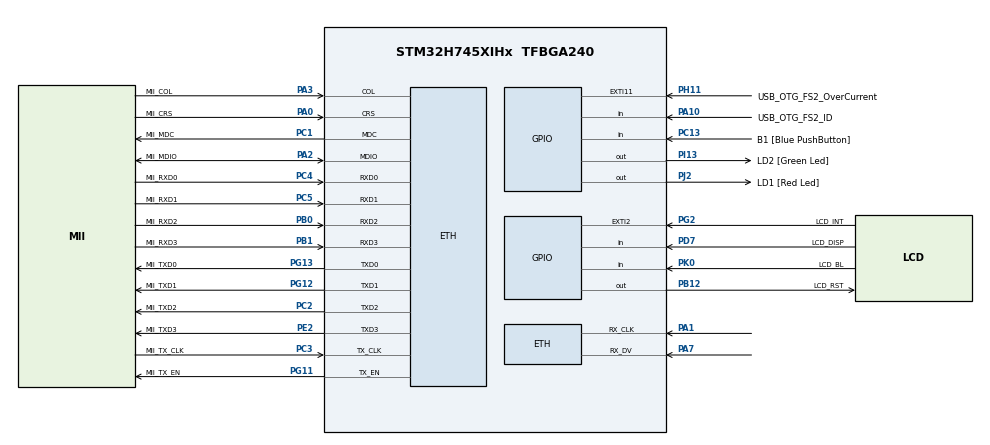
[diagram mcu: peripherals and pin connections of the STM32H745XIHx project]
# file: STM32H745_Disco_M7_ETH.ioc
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CORTEX_M7.AccessPermission_S-Cortex_Memory_Protection_Unit_Region1_Settings_S=MPU_REGION_FULL_ACCESS
CORTEX_M7.AccessPermission_S-Cortex_Memory_Protection_Unit_Region2_Settings_S=MPU_REGION_FULL_ACCESS
CORTEX_M7.BaseAddress_S-Cortex_Memory_Protection_Unit_Region1_Settings_S=0x30020000
CORTEX_M7.BaseAddress_S-Cortex_Memory_Protection_Unit_Region2_Settings_S=0x30040000
CORTEX_M7.CPU_DCache=Enabled
CORTEX_M7.CPU_ICache=Enabled
CORTEX_M7.DisableExec_S-Cortex_Memory_Protection_Unit_Region1_Settings_S=MPU_INSTRUCTION_ACCESS_DISABLE
CORTEX_M7.DisableExec_S-Cortex_Memory_Protection_Unit_Region2_Settings_S=MPU_INSTRUCTION_ACCESS_DISABLE
CORTEX_M7.Enable_S-Cortex_Memory_Protection_Unit_Region1_Settings_S=MPU_REGION_ENABLE
CORTEX_M7.Enable_S-Cortex_Memory_Protection_Unit_Region2_Settings_S=MPU_REGION_ENABLE
CORTEX_M7.IsBufferable_S-Cortex_Memory_Protection_Unit_Region2_Settings_S=MPU_ACCESS_BUFFERABLE
CORTEX_M7.IsShareable_S-Cortex_Memory_Protection_Unit_Region2_Settings_S=MPU_ACCESS_SHAREABLE
CORTEX_M7.Size_S-Cortex_Memory_Protection_Unit_Region1_Settings_S=MPU_REGION_SIZE_128KB
CORTEX_M7.Size_S-Cortex_Memory_Protection_Unit_Region2_Settings_S=MPU_REGION_SIZE_512B
CORTEX_M7.TypeExtField_S-Cortex_Memory_Protection_Unit_Region1_Settings_S=MPU_TEX_LEVEL1
CORTEX_M7.default_mode_Activation=1
CortexM4.IPs=FATFS_M4\:I,FREERTOS_M4\:I,IWDG2\:I,RCC,USB_DEVICE_M4\:I,USB_HOST_M4\:I,WWDG2\:I,DMA,BDMA,MDMA,NVIC2\:I,SAI4\:I,DEBUG,PDM2PCM_M4\:I,PWR,RESMGR_UTILITY,SYS_M4\:I,CORTEX_M4\:I,OPENAMP_M4\:I,VREFBUF
CortexM7.IPs=FATFS_M7\:I,FREERTOS_M7\:I,IWDG1\:I,RCC\:I,USB_DEVICE_M7\:I,USB_HOST_M7\:I,WWDG1\:I,DMA\:I,BDMA\:I,MDMA\:I,NVIC1\:I,CORTEX_M7\:I,DEBUG\:I,PDM2PCM_M7\:I,PWR\:I,RESMGR_UTILITY\:I,SYS\:I,OPENAMP_M7\:I,VREFBUF\:I,TIM6\:I,ETH\:I,LWIP\:I
ETH.MediaInterface=HAL_ETH_MII_MODE
ETH.RxBuffAddress=0x30000200
ETH.RxBuffLen=1536
ETH.TxDescAddress=0x30000100
FREERTOS_M7.Tasks01=defaultTask,24,512,StartDefaultTask,Default,NULL,Dynamic,NULL,NULL
FREERTOS_M7.configCHECK_FOR_STACK_OVERFLOW=1
FREERTOS_M7.configMINIMAL_STACK_SIZE=512
FREERTOS_M7.configTOTAL_HEAP_SIZE=30*1024
FREERTOS_M7.configUSE_NEWLIB_REENTRANT=1
LWIP.BSP.number=1
LWIP.DEFAULT_THREAD_STACKSIZE=2048
LWIP.IP_ADDRESS=192.168.001.010
LWIP.LWIP_DHCP=0
LWIP.LWIP_RAM_HEAP_POINTER=0x30020000
LWIP.MEM_SIZE=131048
LWIP.NETMASK_ADDRESS=255.255.255.000
LWIP.TCPIP_THREAD_STACKSIZE=2048
LWIP.TCP_MSS=1460
LWIP.TCP_SND_BUF=5840
LWIP.TCP_SND_QUEUELEN=16
LWIP.Version=v2.1.2_Cube
LWIP0.BSP.STBoard=false
LWIP0.BSP.api=BSP_COMPONENT_DRIVER
LWIP0.BSP.component=LAN8742
LWIP0.BSP.i2caddr=0
LWIP0.BSP.instance=LAN8742
LWIP0.BSP.name=Driver_PHY
LWIP0.BSP.semaphore=S_LAN8742
LWIP0.BSP.solution=LAN8742
Mcu.Family=STM32H7
Mcu.Name=STM32H745XIHx
Mcu.Package=TFBGA240
NVIC1.ETH_IRQn=true\:5\:0\:false\:false\:true\:true\:true\:true\:true
NVIC1.PriorityGroup=NVIC_PRIORITYGROUP_4
NVIC1.TIM6_DAC_IRQn=true\:15\:0\:false\:false\:true\:false\:false\:true\:true
NVIC1.TimeBase=TIM6_DAC_IRQn
NVIC1.TimeBaseIP=TIM6
NVIC2.PriorityGroup=NVIC_PRIORITYGROUP_4
PA0.GPIO_Label=MII_CRS
PA0.GPIO_Speed=GPIO_SPEED_FREQ_VERY_HIGH
PA0.Mode=MII
PA0.PinAttribute=CortexM7
PA0.Signal=ETH_CRS
PA1.GPIO_Speed=GPIO_SPEED_FREQ_VERY_HIGH
PA1.Mode=MII
PA1.PinAttribute=CortexM7
PA1.Signal=ETH_RX_CLK
PA10.GPIO_Label=USB_OTG_FS2_ID
PA10.PinAttribute=Free
PA10.Signal=GPIO_Input
PA11.GPIO_Label=USB_OTG_FS2_N
PA11.Signal=USB_OTG_FS_DM
PA12.GPIO_Label=USB_OTG_FS2_P
PA12.Signal=USB_OTG_FS_DP
PA2.GPIO_Label=MII_MDIO
PA2.GPIO_Speed=GPIO_SPEED_FREQ_VERY_HIGH
PA2.Mode=MII
PA2.PinAttribute=CortexM7
PA2.Signal=ETH_MDIO
PA3.GPIO_Label=MII_COL
PA3.GPIO_Speed=GPIO_SPEED_FREQ_VERY_HIGH
PA3.Mode=MII
PA3.PinAttribute=CortexM7
PA3.Signal=ETH_COL
PA7.GPIO_Speed=GPIO_SPEED_FREQ_VERY_HIGH
PA7.Mode=MII
PA7.PinAttribute=CortexM7
PA7.Signal=ETH_RX_DV
PA9.GPIO_Label=VBUS_FS2
PA9.Signal=USB_OTG_FS_VBUS
PB0.GPIO_Label=MII_RXD2
PB0.GPIO_Speed=GPIO_SPEED_FREQ_VERY_HIGH
PB0.Mode=MII
PB0.PinAttribute=CortexM7
PB0.Signal=ETH_RXD2
PB1.GPIO_Label=MII_RXD3
PB1.GPIO_Speed=GPIO_SPEED_FREQ_VERY_HIGH
PB1.Mode=MII
PB1.PinAttribute=CortexM7
PB1.Signal=ETH_RXD3
PB10.GPIO_Label=VCP_TX
PB10.Signal=USART3_TX
PB11.GPIO_Label=VCP_RX
PB11.Signal=USART3_RX
PB12.GPIO_Label=LCD_RST
PB12.PinAttribute=Free
PB12.Signal=GPIO_Output
PB13.GPIO_Label=FDCAN2_TX
PB13.Signal=FDCAN2_TX
PB5.GPIO_Label=FDCAN2_RX
PB5.Signal=FDCAN2_RX
PB6.Signal=QUADSPI_BK1_NCS
PB8.GPIO_Label=SDIO1_D4
PB8.Signal=SDMMC1_D4
PB9.GPIO_Label=SDIO1_D5
PB9.Signal=SDMMC1_D5
PC1.GPIO_Label=MII_MDC
PC1.GPIO_Speed=GPIO_SPEED_FREQ_VERY_HIGH
PC1.Mode=MII
PC1.PinAttribute=CortexM7
PC1.Signal=ETH_MDC
PC10.GPIO_Label=SDIO1_D2
PC10.Signal=SDMMC1_D2
PC11.GPIO_Label=SDIO1_D3
PC11.Signal=SDMMC1_D3
PC12.GPIO_Label=SDIO1_CK
PC12.Signal=SDMMC1_CK
PC13.GPIO_Label=B1 [Blue PushButton]
PC13.PinAttribute=Free
PC13.Signal=GPIO_Input
PC14-OSC32_IN\ (OSC32_IN).GPIO_Label=OSC32_IN
PC14-OSC32_IN\ (OSC32_IN).PinAttribute=CortexM7
PC14-OSC32_IN\ (OSC32_IN).Signal=RCC_OSC32_IN
PC15-OSC32_OUT\ (OSC32_OUT).GPIO_Label=OSC32_OUT
PC15-OSC32_OUT\ (OSC32_OUT).PinAttribute=CortexM7
PC15-OSC32_OUT\ (OSC32_OUT).Signal=RCC_OSC32_OUT
PC2.GPIO_Label=MII_TXD2
PC2.GPIO_Speed=GPIO_SPEED_FREQ_VERY_HIGH
PC2.Mode=MII
PC2.PinAttribute=CortexM7
PC2.Signal=ETH_TXD2
PC3.GPIO_Label=MII_TX_CLK
PC3.GPIO_Speed=GPIO_SPEED_FREQ_VERY_HIGH
PC3.Mode=MII
PC3.PinAttribute=CortexM7
PC3.Signal=ETH_TX_CLK
PC4.GPIO_Label=MII_RXD0
PC4.GPIO_Speed=GPIO_SPEED_FREQ_VERY_HIGH
PC4.Mode=MII
PC4.PinAttribute=CortexM7
PC4.Signal=ETH_RXD0
PC5.GPIO_Label=MII_RXD1
PC5.GPIO_Speed=GPIO_SPEED_FREQ_VERY_HIGH
PC5.Mode=MII
PC5.PinAttribute=CortexM7
PC5.Signal=ETH_RXD1
PC6.GPIO_Label=SDIO1_D6
PC6.Signal=SDMMC1_D6
PC7.GPIO_Label=SDIO1_D7
PC7.Signal=SDMMC1_D7
PC8.GPIO_Label=SDIO1_D0
PC8.Signal=SDMMC1_D0
PC9.GPIO_Label=SDIO1_D1
PC9.Signal=SDMMC1_D1
PD0.Signal=FMC_D2_DA2
PD1.Signal=FMC_D3_DA3
PD10.Signal=FMC_D15_DA15
PD11.Signal=QUADSPI_BK1_IO0
PD14.Signal=FMC_D0_DA0
PD15.Signal=FMC_D1_DA1
PD2.GPIO_Label=SDIO1_CMD
PD2.Signal=SDMMC1_CMD
PD7.GPIO_Label=LCD_DISP
PD7.PinAttribute=Free
PD7.Signal=GPIO_Input
PD8.Signal=FMC_D13_DA13
PD9.Signal=FMC_D14_DA14
PE0.Signal=FMC_NBL0
PE1.Signal=FMC_NBL1
PE10.Signal=FMC_D7_DA7
PE11.Signal=FMC_D8_DA8
PE12.Signal=FMC_D9_DA9
PE13.Signal=FMC_D10_DA10
PE14.Signal=FMC_D11_DA11
PE15.Signal=FMC_D12_DA12
PE2.GPIO_Label=MII_TXD3
PE2.GPIO_Speed=GPIO_SPEED_FREQ_VERY_HIGH
PE2.Mode=MII
PE2.PinAttribute=CortexM7
PE2.Signal=ETH_TXD3
PE4.PinAttribute=CortexM4
PE4.Signal=SAI4_D2
PE5.PinAttribute=CortexM4
PE5.Signal=SAI4_CK2
PE7.Signal=FMC_D4_DA4
PE8.Signal=FMC_D5_DA5
PE9.Signal=FMC_D6_DA6
PF0.Signal=FMC_A0
PF1.Signal=FMC_A1
PF10.Signal=QUADSPI_CLK
PF11.Signal=FMC_SDNRAS
PF12.Signal=FMC_A6
PF13.Signal=FMC_A7
PF14.Signal=FMC_A8
PF15.Signal=FMC_A9
PF2.Signal=FMC_A2
PF3.Signal=FMC_A3
PF4.Signal=FMC_A4
PF5.Signal=FMC_A5
PF6.Signal=QUADSPI_BK1_IO3
PF7.Signal=QUADSPI_BK1_IO2
PF9.Signal=QUADSPI_BK1_IO1
PG0.Signal=FMC_A10
PG1.Signal=FMC_A11
PG10.Signal=SAI2_SD_B
PG11.GPIO_Label=MII_TX_EN
PG11.GPIO_Speed=GPIO_SPEED_FREQ_VERY_HIGH
PG11.Mode=MII
PG11.PinAttribute=CortexM7
PG11.Signal=ETH_TX_EN
PG12.GPIO_Label=MII_TXD1
PG12.GPIO_Speed=GPIO_SPEED_FREQ_VERY_HIGH
PG12.Mode=MII
PG12.PinAttribute=CortexM7
PG12.Signal=ETH_TXD1
PG13.GPIO_Label=MII_TXD0
PG13.GPIO_Speed=GPIO_SPEED_FREQ_VERY_HIGH
PG13.Mode=MII
PG13.PinAttribute=CortexM7
PG13.Signal=ETH_TXD0
PG15.Signal=FMC_SDNCAS
PG2.GPIO_Label=LCD_INT
PG2.PinAttribute=Free
PG2.Signal=GPXTI2
PG4.Signal=FMC_A14_BA0
PG5.Signal=FMC_A15_BA1
PG8.Signal=FMC_SDCLK
PH0-OSC_IN\ (PH0).GPIO_Label=OSC_IN
PH0-OSC_IN\ (PH0).PinAttribute=CortexM7
PH0-OSC_IN\ (PH0).Signal=RCC_OSC_IN
PH1-OSC_OUT\ (PH1).GPIO_Label=OSC_OUT
PH1-OSC_OUT\ (PH1).PinAttribute=CortexM7
PH1-OSC_OUT\ (PH1).Signal=RCC_OSC_OUT
PH11.GPIO_Label=USB_OTG_FS2_OverCurrent
PH11.PinAttribute=Free
PH11.Signal=GPXTI11
PH13.GPIO_Label=FDCAN1_TX
PH13.Signal=FDCAN1_TX
PH14.GPIO_Label=FDCAN2_RX
PH14.Signal=FDCAN1_RX
PH5.Signal=FMC_SDNWE
PH6.Signal=FMC_SDNE1
PH7.Signal=FMC_SDCKE1
PH9.Signal=LTDC_R3
PI0.Signal=LTDC_G5
PI1.Signal=LTDC_G6
PI10.GPIO_Label=MII_RX_ER
PI10.PinAttribute=CortexM7
PI10.Signal=ETH_RX_ER
PI12.Signal=LTDC_HSYNC
PI13.GPIO_Label=LD2 [Green Led]
PI13.PinAttribute=Free
PI13.Signal=GPIO_Output
PI14.Signal=LTDC_CLK
PI15.Signal=LTDC_R0
PI4.Signal=SAI2_MCLK_A
PI5.Signal=SAI2_SCK_A
PI6.Signal=SAI2_SD_A
PI7.Signal=SAI2_FS_A
PI9.Signal=LTDC_VSYNC
PJ0.Signal=LTDC_R1
PJ1.Signal=LTDC_R2
PJ10.Signal=LTDC_G3
PJ11.Signal=LTDC_G4
PJ12.Signal=LTDC_B0
PJ13.Signal=LTDC_B1
PJ14.Signal=LTDC_B2
PJ15.GPIO_Label=LCD_DISP
PJ15.Signal=LTDC_B3
PJ2.GPIO_Label=LD1 [Red Led]
PJ2.PinAttribute=Free
PJ2.Signal=GPIO_Output
PJ3.Signal=LTDC_R4
PJ4.Signal=LTDC_R5
PJ5.Signal=LTDC_R6
PJ6.Signal=LTDC_R7
PJ7.Signal=LTDC_G0
PJ8.Signal=LTDC_G1
PJ9.Signal=LTDC_G2
PK0.GPIO_Label=LCD_BL
PK0.PinAttribute=Free
PK0.Signal=GPIO_Input
PK2.Signal=LTDC_G7
PK3.Signal=LTDC_B4
PK4.Signal=LTDC_B5
PK5.Signal=LTDC_B6
PK6.Signal=LTDC_B7
PK7.Signal=LTDC_DE
ProjectManager.HeapSize=M4-0x200,M7-0x200
ProjectManager.StackSize=M4-0x400,M7-0x400
ProjectManager.TargetToolchain=STM32CubeIDE
RCC.ADCFreq_Value=129000000
RCC.APB1Freq_Value=100000000
RCC.APB2Freq_Value=100000000
RCC.APB3Freq_Value=100000000
RCC.APB4Freq_Value=100000000
RCC.CortexFreq_Value=400000000
RCC.D1PPRE=RCC_APB3_DIV2
RCC.D2PPRE1=RCC_APB1_DIV2
RCC.D2PPRE2=RCC_APB2_DIV2
RCC.D3PPRE=RCC_APB4_DIV2
RCC.DIVN1=400
RCC.DIVQ1=4
RCC.DIVR1=4
RCC.HCLKFreq_Value=200000000
RCC.HPRE=RCC_HCLK_DIV2
RCC.PLL2FRACN=0
RCC.PLL3FRACN=0
RCC.PLLFRACN=0
RCC.SYSCLKFreq_VALUE=400000000
RCC.SYSCLKSource=RCC_SYSCLKSOURCE_PLLCLK
RCC.SupplySource=PWR_DIRECT_SMPS_SUPPLY
RCC.USBFreq_Value=200000000
SH.FMC_A0.0=FMC_A0
SH.FMC_A1.0=FMC_A1
SH.FMC_A10.0=FMC_A10
SH.FMC_A11.0=FMC_A11
SH.FMC_A14_BA0.0=FMC_BA0
SH.FMC_A15_BA1.0=FMC_BA1
SH.FMC_A2.0=FMC_A2
SH.FMC_A3.0=FMC_A3
SH.FMC_A4.0=FMC_A4
SH.FMC_A5.0=FMC_A5
SH.FMC_A6.0=FMC_A6
SH.FMC_A7.0=FMC_A7
SH.FMC_A8.0=FMC_A8
SH.FMC_A9.0=FMC_A9
SH.FMC_D0_DA0.0=FMC_D0
SH.FMC_D10_DA10.0=FMC_D10
SH.FMC_D11_DA11.0=FMC_D11
SH.FMC_D12_DA12.0=FMC_D12
SH.FMC_D13_DA13.0=FMC_D13
SH.FMC_D14_DA14.0=FMC_D14
SH.FMC_D15_DA15.0=FMC_D15
SH.FMC_D1_DA1.0=FMC_D1
SH.FMC_D2_DA2.0=FMC_D2
SH.FMC_D3_DA3.0=FMC_D3
SH.FMC_D4_DA4.0=FMC_D4
SH.FMC_D5_DA5.0=FMC_D5
SH.FMC_D6_DA6.0=FMC_D6
SH.FMC_D7_DA7.0=FMC_D7
SH.FMC_D8_DA8.0=FMC_D8
SH.FMC_D9_DA9.0=FMC_D9
SH.FMC_NBL0.0=FMC_NBL0
SH.FMC_NBL1.0=FMC_NBL1
SH.FMC_SDCLK.0=FMC_SDCLK
SH.FMC_SDNCAS.0=FMC_SDNCAS
SH.FMC_SDNRAS.0=FMC_SDNRAS
SH.FMC_SDNWE.0=FMC_SDNWE
VP_FREERTOS_M7_VS_CMSIS_V2.Mode=CMSIS_V2
VP_LWIP_VS_Enabled.Mode=Enabled
VP_SYS_M4_VS_Systick.Mode=SysTick
VP_SYS_VS_tim6.Mode=TIM6
board=STM32H745I-DISCO

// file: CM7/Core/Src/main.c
/* USER CODE BEGIN Header */
/**
  ******************************************************************************
  * @file           : main.c
  * @brief          : Main program body
  ******************************************************************************
  * @attention
  *
  * Copyright (c) 2022 STMicroelectronics.
  * All rights reserved.
  *
  * This software is licensed under terms that can be found in the LICENSE file
  * in the root directory of this software component.
  * If no LICENSE file comes with this software, it is provided AS-IS.
  *
  ******************************************************************************
  */
/* USER CODE END Header */
#include "main.h"
#include "cmsis_os.h"
#include "lwip.h"

/* USER CODE BEGIN Includes */
/* ETH_CODE: add lwiperf, see comment in StartDefaultTask function */
#include "lwip/apps/lwiperf.h"
/* USER CODE END Includes */

/* USER CODE BEGIN PD */

#ifndef HSEM_ID_0
#define HSEM_ID_0 (0U) /* HW semaphore 0*/
#endif
/* USER CODE END PD */

/* Definitions for defaultTask */
osThreadId_t defaultTaskHandle;
const osThreadAttr_t defaultTask_attributes = {
  .name = "defaultTask",
  .stack_size = 512 * 4,
  .priority = (osPriority_t) osPriorityNormal,
};

void SystemClock_Config(void);
static void MPU_Config(void);
static void MX_GPIO_Init(void);
void StartDefaultTask(void *argument);

int main(void)
{
/* USER CODE BEGIN Boot_Mode_Sequence_0 */

/* USER CODE END Boot_Mode_Sequence_0 */

  /* MPU Configuration--------------------------------------------------------*/
  MPU_Config();

  /* Enable I-Cache---------------------------------------------------------*/
  SCB_EnableICache();

  /* Enable D-Cache---------------------------------------------------------*/
  SCB_EnableDCache();

/* USER CODE BEGIN Boot_Mode_Sequence_1 */

/* USER CODE END Boot_Mode_Sequence_1 */
  /* MCU Configuration--------------------------------------------------------*/

  /* Reset of all peripherals, Initializes the Flash interface and the Systick. */
  HAL_Init();

  /* Configure the system clock */
  SystemClock_Config();
/* USER CODE BEGIN Boot_Mode_Sequence_2 */

/* USER CODE END Boot_Mode_Sequence_2 */

  /* Initialize all configured peripherals */
  MX_GPIO_Init();
  /* USER CODE BEGIN 2 */
  /* ETH_CODE: fixed core synchronization
     * Release M4 core after GPIO and peripherals init
     * to avoid conflict.
     */
    __HAL_RCC_HSEM_CLK_ENABLE();
    HAL_HSEM_FastTake(HSEM_ID_0);
    HAL_HSEM_Release(HSEM_ID_0,0);
  /* USER CODE END 2 */

  /* Init scheduler */
  osKernelInitialize();

  /* Create the thread(s) */
  /* creation of defaultTask */
  defaultTaskHandle = osThreadNew(StartDefaultTask, NULL, &defaultTask_attributes);

  /* Start scheduler */
  osKernelStart();

  /* We should never get here as control is now taken by the scheduler */
  /* Infinite loop */
  while (1)
  {

  }
}

void SystemClock_Config(void)
{
  RCC_OscInitTypeDef RCC_OscInitStruct = {0};
  RCC_ClkInitTypeDef RCC_ClkInitStruct = {0};

  /** Supply configuration update enable
  */
  HAL_PWREx_ConfigSupply(PWR_DIRECT_SMPS_SUPPLY);

  /** Configure the main internal regulator output voltage
  */
  __HAL_PWR_VOLTAGESCALING_CONFIG(PWR_REGULATOR_VOLTAGE_SCALE1);

  while(!__HAL_PWR_GET_FLAG(PWR_FLAG_VOSRDY)) {}

  /** Initializes the RCC Oscillators according to the specified parameters
  * in the RCC_OscInitTypeDef structure.
  */
  RCC_OscInitStruct.OscillatorType = RCC_OSCILLATORTYPE_HSI;
  RCC_OscInitStruct.HSIState = RCC_HSI_DIV1;
  RCC_OscInitStruct.HSICalibrationValue = RCC_HSICALIBRATION_DEFAULT;
  RCC_OscInitStruct.PLL.PLLState = RCC_PLL_ON;
  RCC_OscInitStruct.PLL.PLLSource = RCC_PLLSOURCE_HSI;
  RCC_OscInitStruct.PLL.PLLM = 32;
  RCC_OscInitStruct.PLL.PLLN = 400;
  RCC_OscInitStruct.PLL.PLLP = 2;
  RCC_OscInitStruct.PLL.PLLQ = 4;
  RCC_OscInitStruct.PLL.PLLR = 4;
  RCC_OscInitStruct.PLL.PLLRGE = RCC_PLL1VCIRANGE_1;
  RCC_OscInitStruct.PLL.PLLVCOSEL = RCC_PLL1VCOWIDE;
  RCC_OscInitStruct.PLL.PLLFRACN = 0;
  if (HAL_RCC_OscConfig(&RCC_OscInitStruct) != HAL_OK)
  {
    Error_Handler();
  }

  /** Initializes the CPU, AHB and APB buses clocks
  */
  RCC_ClkInitStruct.ClockType = RCC_CLOCKTYPE_HCLK|RCC_CLOCKTYPE_SYSCLK
                              |RCC_CLOCKTYPE_PCLK1|RCC_CLOCKTYPE_PCLK2
                              |RCC_CLOCKTYPE_D3PCLK1|RCC_CLOCKTYPE_D1PCLK1;
  RCC_ClkInitStruct.SYSCLKSource = RCC_SYSCLKSOURCE_PLLCLK;
  RCC_ClkInitStruct.SYSCLKDivider = RCC_SYSCLK_DIV1;
  RCC_ClkInitStruct.AHBCLKDivider = RCC_HCLK_DIV2;
  RCC_ClkInitStruct.APB3CLKDivider = RCC_APB3_DIV2;
  RCC_ClkInitStruct.APB1CLKDivider = RCC_APB1_DIV2;
  RCC_ClkInitStruct.APB2CLKDivider = RCC_APB2_DIV2;
  RCC_ClkInitStruct.APB4CLKDivider = RCC_APB4_DIV2;

  if (HAL_RCC_ClockConfig(&RCC_ClkInitStruct, FLASH_LATENCY_2) != HAL_OK)
  {
    Error_Handler();
  }
}

static void MX_GPIO_Init(void)
{

  /* GPIO Ports Clock Enable */
  __HAL_RCC_GPIOG_CLK_ENABLE();
  __HAL_RCC_GPIOC_CLK_ENABLE();
  __HAL_RCC_GPIOE_CLK_ENABLE();
  __HAL_RCC_GPIOI_CLK_ENABLE();
  __HAL_RCC_GPIOH_CLK_ENABLE();
  __HAL_RCC_GPIOA_CLK_ENABLE();
  __HAL_RCC_GPIOB_CLK_ENABLE();

}

void StartDefaultTask(void *argument)
{
  /* init code for LWIP */
  MX_LWIP_Init();
  /* USER CODE BEGIN 5 */
  /* ETH_CODE: Adding lwiperf to measure TCP/IP performance.
     * iperf 2.0.6 (or older?) is required for the tests. Newer iperf2 versions
     * might work without data check, but they send different headers.
     * iperf3 is not compatible at all.
     * Adding lwiperf.c file to the project is necessary.
     * The default include path should already contain
     * 'lwip/apps/lwiperf.h'
     */
    LOCK_TCPIP_CORE();
    lwiperf_start_tcp_server_default(NULL, NULL);

    ip4_addr_t remote_addr;
    IP4_ADDR(&remote_addr, 192, 168, 1, 1);
    lwiperf_start_tcp_client_default(&remote_addr, NULL, NULL);
    UNLOCK_TCPIP_CORE();
    /* Infinite loop */
    for(;;)
    {
      osDelay(1000);
    }
  /* USER CODE END 5 */
}

/* MPU Configuration */

void MPU_Config(void)
{
  MPU_Region_InitTypeDef MPU_InitStruct = {0};

  /* Disables the MPU */
  HAL_MPU_Disable();

  /** Initializes and configures the Region and the memory to be protected
  */
  MPU_InitStruct.Enable = MPU_REGION_ENABLE;
  MPU_InitStruct.Number = MPU_REGION_NUMBER0;
  MPU_InitStruct.BaseAddress = 0x0;
  MPU_InitStruct.Size = MPU_REGION_SIZE_4GB;
  MPU_InitStruct.SubRegionDisable = 0x87;
  MPU_InitStruct.TypeExtField = MPU_TEX_LEVEL0;
  MPU_InitStruct.AccessPermission = MPU_REGION_NO_ACCESS;
  MPU_InitStruct.DisableExec = MPU_INSTRUCTION_ACCESS_DISABLE;
  MPU_InitStruct.IsShareable = MPU_ACCESS_SHAREABLE;
  MPU_InitStruct.IsCacheable = MPU_ACCESS_NOT_CACHEABLE;
  MPU_InitStruct.IsBufferable = MPU_ACCESS_NOT_BUFFERABLE;

  HAL_MPU_ConfigRegion(&MPU_InitStruct);

  /** Initializes and configures the Region and the memory to be protected
  */
  MPU_InitStruct.Number = MPU_REGION_NUMBER1;
  MPU_InitStruct.BaseAddress = 0x30020000;
  MPU_InitStruct.Size = MPU_REGION_SIZE_128KB;
  MPU_InitStruct.SubRegionDisable = 0x0;
  MPU_InitStruct.TypeExtField = MPU_TEX_LEVEL1;
  MPU_InitStruct.AccessPermission = MPU_REGION_FULL_ACCESS;
  MPU_InitStruct.IsShareable = MPU_ACCESS_NOT_SHAREABLE;

  HAL_MPU_ConfigRegion(&MPU_InitStruct);

  /** Initializes and configures the Region and the memory to be protected
  */
  MPU_InitStruct.Number = MPU_REGION_NUMBER2;
  MPU_InitStruct.BaseAddress = 0x30040000;
  MPU_InitStruct.Size = MPU_REGION_SIZE_512B;
  MPU_InitStruct.TypeExtField = MPU_TEX_LEVEL0;
  MPU_InitStruct.IsShareable = MPU_ACCESS_SHAREABLE;
  MPU_InitStruct.IsBufferable = MPU_ACCESS_BUFFERABLE;

  HAL_MPU_ConfigRegion(&MPU_InitStruct);
  /* Enables the MPU */
  HAL_MPU_Enable(MPU_PRIVILEGED_DEFAULT);

}

void HAL_TIM_PeriodElapsedCallback(TIM_HandleTypeDef *htim)
{
  if (htim->Instance == TIM6) {
    HAL_IncTick();
  }
}

void Error_Handler(void)
{
  __disable_irq();
  while (1)
  {
  }
}
